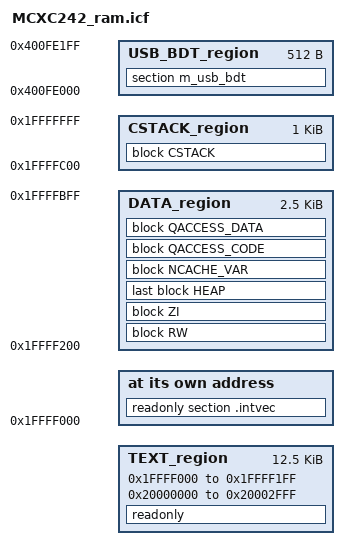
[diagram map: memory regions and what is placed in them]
/*
** ###################################################################
**     Processors:          MCXC242VFM
**                          MCXC242VLH
**
**     Compiler:            IAR ANSI C/C++ Compiler for ARM
**     Reference manual:    MCXC242RM, Rev.1, Mar 2024
**     Version:             rev. 1.5, 2025-11-07
**     Build:               b251107
**
**     Abstract:
**         Linker file for the IAR ANSI C/C++ Compiler for ARM
**
**     Copyright 2016 Freescale Semiconductor, Inc.
**     Copyright 2016-2025 NXP
**     SPDX-License-Identifier: BSD-3-Clause
**
**     http:                 www.nxp.com
**     mail:                 support@nxp.com
**
** ###################################################################
*/

define symbol m_interrupts_start       = 0x1FFFF000;
define symbol m_interrupts_end         = 0x1FFFF1FF;

define symbol m_data_start             = 0x1FFFF200;
define symbol m_data_end               = 0x1FFFFFFF;

define symbol m_text_start             = 0x20000000;
define symbol m_text_end               = 0x20002FFF;

define symbol m_usb_sram_start         = 0x400FE000;
define symbol m_usb_sram_end           = 0x400FE1FF;

/* USB BDT size */
define symbol usb_bdt_size             = 0x200;
/* Sizes */
if (isdefinedsymbol(__stack_size__)) {
  define symbol __size_cstack__        = __stack_size__;
} else {
  define symbol __size_cstack__        = 0x0400;
}

if (isdefinedsymbol(__heap_size__)) {
  define symbol __size_heap__          = __heap_size__;
} else {
  define symbol __size_heap__          = 0x0400;
}


define memory mem with size = 4G;
define region TEXT_region = mem:[from m_interrupts_start to m_interrupts_end]
                          | mem:[from m_text_start to m_text_end];
define region DATA_region = mem:[from m_data_start to m_data_end-__size_cstack__];
define region CSTACK_region = mem:[from m_data_end-__size_cstack__+1 to m_data_end];

define block CSTACK    with alignment = 8, size = __size_cstack__   { };
define block HEAP      with alignment = 8, size = __size_heap__     { };
define block RW        { readwrite };
define block ZI        { zi };
define block NCACHE_VAR    { section NonCacheable , section NonCacheable.init };
define block QACCESS_CODE  { section CodeQuickAccess };
define block QACCESS_DATA  { section DataQuickAccess };

/* regions for USB */
define region USB_BDT_region = mem:[from m_usb_sram_start to m_usb_sram_start + usb_bdt_size - 1];
place in USB_BDT_region                     { section m_usb_bdt };

initialize by copy { readwrite, section .textrw, section CodeQuickAccess, section DataQuickAccess };
do not initialize  { section .noinit, section m_usb_bdt };

place at address mem: m_interrupts_start    { readonly section .intvec };
place in TEXT_region                        { readonly };
place in DATA_region                        { block RW };
place in DATA_region                        { block ZI };
place in DATA_region                        { last block HEAP };
place in CSTACK_region                      { block CSTACK };
place in DATA_region                        { block NCACHE_VAR };
place in DATA_region                        { block QACCESS_CODE };
place in DATA_region                        { block QACCESS_DATA };

